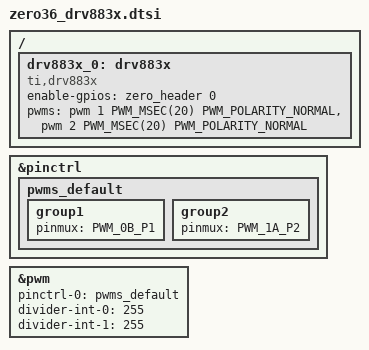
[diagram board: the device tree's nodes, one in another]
/*
 * Copyright (c) 2020 Pete Johanson
 *
 * SPDX-License-Identifier: MIT
 */

#include <dt-bindings/pinctrl/rpi-pico-rp2040-pinctrl.h>
#include <zephyr/dt-bindings/pwm/pwm.h>

&pinctrl {
    pwms_default: pwms_default {
        group1 {
            pinmux = <PWM_0B_P1>;
        };
        group2 {
            pinmux = <PWM_1A_P2>;
        };
    };
};

&pwm {
    // compatible = "raspberrypi,pico-pwm";
    status = "okay";
    pinctrl-0 = <&pwms_default>;
    pinctrl-names = "default";
    divider-int-0 = <255>;
    divider-int-1 = <255>;
};

/ {
  drv883x_0: drv883x {
    compatible = "ti,drv883x";

    enable-gpios = <&zero_header 0 (GPIO_ACTIVE_HIGH | GPIO_PULL_DOWN)>;

    /* map PWM gpios to IN1 / IN2 pin on drv883x */
    /* set N in <&pwm N ...>, where N is refering to group<N> from above &pinctrl */
    pwms = <&pwm 1 PWM_MSEC(20) PWM_POLARITY_NORMAL>
         , <&pwm 2 PWM_MSEC(20) PWM_POLARITY_NORMAL>;

    /* either use plain gpios if always run at full speed */
    // in1-gpios = <&zero_header 1 (GPIO_ACTIVE_HIGH | GPIO_PULL_DOWN)>;
    // in2-gpios = <&zero_header 2 (GPIO_ACTIVE_HIGH | GPIO_PULL_DOWN)>;

  };
};
